VERSION ""

NS_ :

BS_:

BU_:

BO_ 384 GW_180: 8 Vector__XXX
 SG_ SAS_SteeringAngle : 7|16@0- (0.1,-780) [-780|780] "deg" Vector__XXX
 SG_ SAS_SteeringAngleSpeed : 39|8@0+ (1,0) [0|255] "deg/s" Vector__XXX

BO_ 382 GW_17E: 8 Vector__XXX
 SG_ EPS_MeasuredTorsionBarTorque : 13|14@0- (0.01,-32) [-32|32] "Nm" Vector__XXX
 SG_ EPS_LatCtrlAvailabilityStatus : 23|2@0+ (1,0) [0|3] "" Vector__XXX
 SG_ EPS_RollingCounter_17E : 51|4@0+ (1,0) [0|15] "" Vector__XXX

BO_ 442 GW_1BA: 32 Vector__XXX
 SG_ ACC_RollingCounter_1BA : 51|4@0+ (1,0) [0|15] "" Vector__XXX
 SG_ ACC_SteeringAngleCmd : 7|16@0- (0.1,-780) [-780|780] "deg" Vector__XXX
 SG_ ACC_SteeringActive : 31|1@0+ (1,0) [0|1] "" Vector__XXX

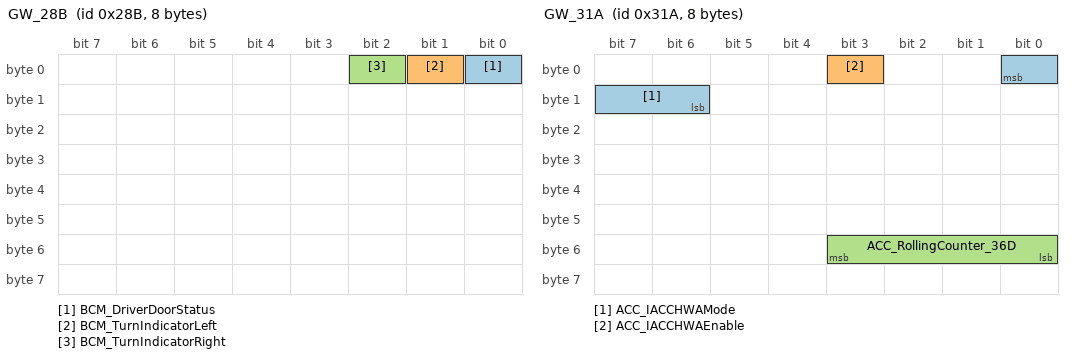
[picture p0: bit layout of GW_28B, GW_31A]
BO_ 651 GW_28B: 8 Vector__XXX
 SG_ BCM_DriverDoorStatus : 0|1@0+ (1,0) [0|1] "" Vector__XXX
 SG_ BCM_TurnIndicatorLeft : 1|1@0+ (1,0) [0|1] "" Vector__XXX
 SG_ BCM_TurnIndicatorRight : 2|1@0+ (1,0) [0|1] "" Vector__XXX

BO_ 406 GW_196: 8 Vector__XXX
 SG_ EMS_BrakePedalStatus : 0|1@0+ (1,0) [0|1] "" Vector__XXX
 SG_ EMS_RealAccPedal : 8|8@0+ (0.392157,0) [0|100] "%" Vector__XXX

BO_ 422 GW_1A6: 8 Vector__XXX
 SG_ EMS_BrakePedalStatus : 0|1@0+ (1,0) [0|1] "" Vector__XXX

BO_ 824 GW_338: 8 Vector__XXX
 SG_ TCU_GearForDisplay : 0|4@0+ (1,0) [0|15] "" Vector__XXX

BO_ 454 GW_1C6: 8 Vector__XXX
 SG_ EMS_RealAccPedal : 8|8@0+ (0.392157,0) [0|100] "%" Vector__XXX

BO_ 378 GW_17A: 8 Vector__XXX
 SG_ ESP_VehicleSpeed : 23|14@0+ (0.05625,0) [0|300] "kph" Vector__XXX

BO_ 391 GW_187: 8 Vector__XXX
 SG_ ESP_VehicleSpeed : 23|14@0+ (0.05625,0) [0|300] "kph" Vector__XXX

BO_ 591 GW_24F: 8 Vector__XXX
 SG_ EPS_EPSFailed : 0|1@0+ (1,0) [0|1] "" Vector__XXX

BO_ 580 GW_244: 8 Vector__XXX
 SG_ ACC_ACCMode : 0|3@0+ (1,0) [0|7] "" Vector__XXX
 SG_ ACC_FCWPreWarning : 3|1@0+ (1,0) [0|1] "" Vector__XXX
 SG_ ACC_AEBCtrlType : 4|3@0+ (1,0) [0|7] "" Vector__XXX
 SG_ ACC_RollingCounter_24E : 51|4@0+ (1,0) [0|15] "" Vector__XXX

BO_ 794 GW_31A: 8 Vector__XXX
 SG_ ACC_IACCHWAMode : 0|3@0+ (1,0) [0|7] "" Vector__XXX
 SG_ ACC_IACCHWAEnable : 3|1@0+ (1,0) [0|1] "" Vector__XXX
 SG_ ACC_RollingCounter_36D : 51|4@0+ (1,0) [0|15] "" Vector__XXX

BO_ 775 GW_307: 8 Vector__XXX
 SG_ ACC_RollingCounter_35E : 51|4@0+ (1,0) [0|15] "" Vector__XXX
 SG_ ACC_DistanceLevel : 0|3@0+ (1,0) [0|7] "" Vector__XXX

BO_ 368 GW_170: 8 Vector__XXX
 SG_ EPS_ActualTorsionBarTorq : 13|14@0- (0.01,-32) [-32|32] "Nm" Vector__XXX

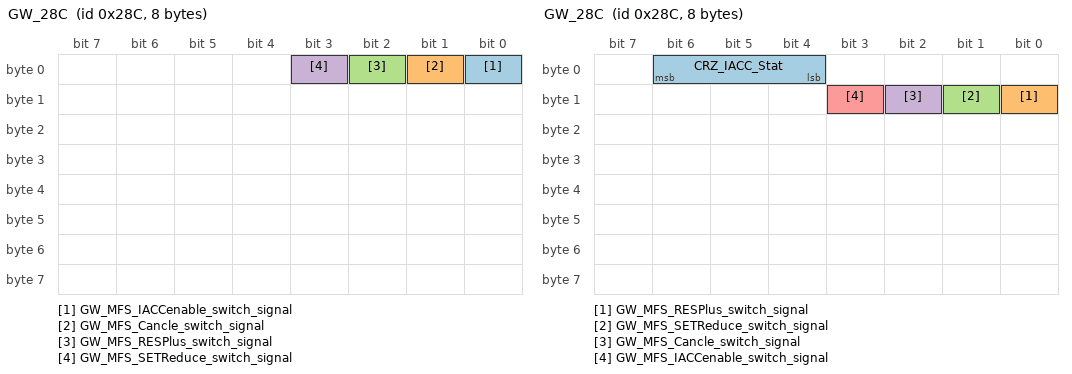
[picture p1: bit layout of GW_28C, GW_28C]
BO_ 652 GW_28C: 8 Vector__XXX
 SG_ GW_MFS_IACCenable_switch_signal : 0|1@0+ (1,0) [0|1] "" Vector__XXX
 SG_ GW_MFS_Cancle_switch_signal : 1|1@0+ (1,0) [0|1] "" Vector__XXX
 SG_ GW_MFS_RESPlus_switch_signal : 2|1@0+ (1,0) [0|1] "" Vector__XXX
 SG_ GW_MFS_SETReduce_switch_signal : 3|1@0+ (1,0) [0|1] "" Vector__XXX

BO_ 80 GW_50: 8 Vector__XXX
 SG_ SRS_DriverBuckleSwitchStatus : 0|1@0+ (1,0) [0|1] "" Vector__XXX

BO_ 817 GW_331: 8 Vector__XXX
 SG_ TCU_GearForDisplay : 0|4@0+ (1,0) [0|15] "" Vector__XXX

BO_ 381 GW_17D: 8 Vector__XXX
 SG_ PCU_BrkPedlSts : 0|1@0+ (1,0) [0|1] "" Vector__XXX
 SG_ PCU_RealAccPedl : 8|8@0+ (0.392157,0) [0|100] "%" Vector__XXX

BO_ 676 GW_2A4: 8 Vector__XXX
 SG_ LCDAR_Left_BSD_LCAAlert : 0|2@0+ (1,0) [0|3] "" Vector__XXX
 SG_ LCDAR_BSD_LCAAlert : 2|2@0+ (1,0) [0|3] "" Vector__XXX

BO_ 652 GW_28C: 8 Vector__XXX
 SG_ CRZ_IACC_Stat : 6|3@0+ (1,0) [0|7] "" Vector__XXX
 SG_ GW_MFS_RESPlus_switch_signal : 8|1@0+ (1,0) [0|1] "" Vector__XXX
 SG_ GW_MFS_SETReduce_switch_signal : 9|1@0+ (1,0) [0|1] "" Vector__XXX
 SG_ GW_MFS_Cancle_switch_signal : 10|1@0+ (1,0) [0|1] "" Vector__XXX
 SG_ GW_MFS_IACCenable_switch_signal : 11|1@0+ (1,0) [0|1] "" Vector__XXX

BO_ 378 GW_17A: 8 Vector__XXX
 SG_ ESP_VehicleSpeed : 21|14@0+ (0.05625,0) [0|300] "km/h" Vector__XXX

BO_ 381 GW_17D: 8 Vector__XXX
 SG_ PCU_RealAccPedl : 55|8@0+ (0.392157,0) [0|100] "%" Vector__XXX
 SG_ PCU_BrkPedlSts : 4|1@0+ (1,0) [0|1] "" Vector__XXX

BO_ 422 GW_1A6: 8 Vector__XXX
 SG_ EMS_BrakePedalStatus : 4|1@0+ (1,0) [0|1] "" Vector__XXX

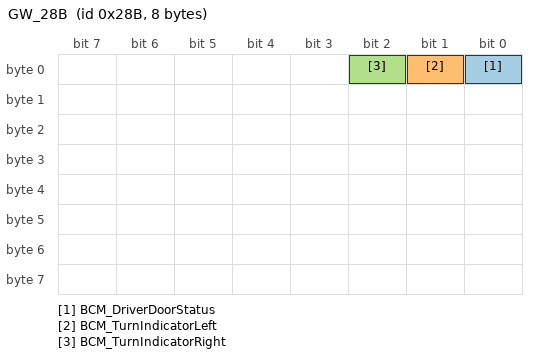
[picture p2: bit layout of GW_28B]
BO_ 651 GW_28B: 8 Vector__XXX
 SG_ BCM_DriverDoorStatus : 0|1@0+ (1,0) [0|1] "" Vector__XXX
 SG_ BCM_TurnIndicatorLeft : 1|1@0+ (1,0) [0|1] "" Vector__XXX
 SG_ BCM_TurnIndicatorRight : 2|1@0+ (1,0) [0|1] "" Vector__XXX

BO_ 80 GW_50: 8 Vector__XXX
 SG_ SRS_DriverBuckleSwitchStatus : 0|1@0+ (1,0) [0|1] "" Vector__XXX

BO_ 391 GW_187: 8 Vector__XXX
 SG_ ESP_VehicleSpeed : 21|14@0+ (0.05625,0) [0|300] "km/h" Vector__XXX

BO_ 406 GW_196: 8 Vector__XXX
 SG_ EMS_BrakePedalStatus : 4|1@0+ (1,0) [0|1] "" Vector__XXX
 SG_ EMS_RealAccPedal : 55|8@0+ (0.392157,0) [0|100] "%" Vector__XXX

BO_ 454 GW_1C6: 8 Vector__XXX
 SG_ EMS_RealAccPedal : 55|8@0+ (0.392157,0) [0|100] "%" Vector__XXX

BO_ 817 GW_331: 8 Vector__XXX
 SG_ TCU_GearForDisplay : 0|4@0+ (1,0) [0|15] "" Vector__XXX

BO_ 824 GW_338: 8 Vector__XXX
 SG_ TCU_GearForDisplay : 0|4@0+ (1,0) [0|15] "" Vector__XXX

BO_ 368 GW_170: 8 Vector__XXX
 SG_ EPS_ActualTorsionBarTorq : 13|14@0- (0.01,-32) [-32|32] "Nm" Vector__XXX

BO_ 591 GW_24F: 8 Vector__XXX
 SG_ EPS_EPSFailed : 0|1@0+ (1,0) [0|1] "" Vector__XXX

BO_ 676 GW_2A4: 8 Vector__XXX
 SG_ LCDAR_Left_BSD_LCAAlert : 0|2@0+ (1,0) [0|3] "" Vector__XXX
 SG_ LCDAR_BSD_LCAAlert : 2|2@0+ (1,0) [0|3] "" Vector__XXX

BO_ 580 GW_244: 8 Vector__XXX
 SG_ ACC_ACCMode : 0|3@0+ (1,0) [0|7] "" Vector__XXX
 SG_ ACC_FCWPreWarning : 3|1@0+ (1,0) [0|1] "" Vector__XXX
 SG_ ACC_AEBCtrlType : 4|2@0+ (1,0) [0|3] "" Vector__XXX

BO_ 794 GW_31A: 8 Vector__XXX
 SG_ ACC_IACCHWAMode : 0|3@0+ (1,0) [0|7] "" Vector__XXX
 SG_ ACC_IACCHWAEnable : 3|1@0+ (1,0) [0|1] "" Vector__XXX

BO_ 442 GW_1BA: 8 Vector__XXX
